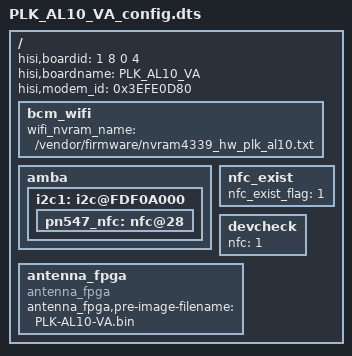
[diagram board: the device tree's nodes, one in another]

/**
 * Huawei Ltd.
 * PhosphorV660
 */

/dts-v1/;

/include/ "fastboot.dtsi"
/include/ "PLK_CL00_VA_config.dtsi"
/include/ "PLK_AL10_VA_pin.dtsi"
/include/ "PLK_AL10_VA_hi6402_pin.dtsi"
/include/ "PLK_AL10_VA_modem_pin.dtsi"
///include/ "PLK_AL10_VA_charger.dtsi"
///include/ "PLK_AL10_VA_pmic.dtsi"
///include/ "PLK_AL10_VA_gpio_logic.dtsi"

/ {
	hisi,boardid = <1 8 0 4 >;
	hisi,boardname = "PLK_AL10_VA";
	hisi,modem_id = <0x3EFE0D80>;
	bcm_wifi {
		wifi_nvram_name = "/vendor/firmware/nvram4339_hw_plk_al10.txt";
	};
	amba {
		i2c1: i2c@FDF0A000 {
			pn547_nfc:nfc@28 {
				status = "ok";
			};
		};
	};
	nfc_exist {
		nfc_exist_flag = "1";
		status = "ok";
	};

	devcheck: devcheck {
		nfc = <1>;
	};

	antenna_fpga{
		compatible = "antenna_fpga";
		antenna_fpga,pre-image-filename = "PLK-AL10-VA.bin";
		status = "ok";
	};
};

